# RL6955_IP_SVD register map
Vendor: Realtek
Registers are 32-bit, read-write, reset 0x0 unless marked. A register's access mark holds for its fields unless they carry their own. Offsets are from the block's base; [hi:lo] are bit positions.

## LDO_REG
Base 0x41000100
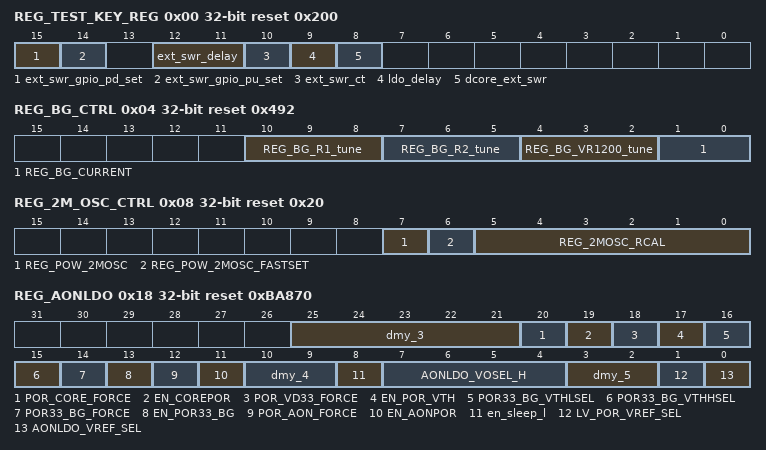
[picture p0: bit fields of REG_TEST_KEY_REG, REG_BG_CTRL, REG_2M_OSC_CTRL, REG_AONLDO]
0x00 REG_TEST_KEY_REG reset 0x200
  [15] ext_swr_gpio_pd_set — Set extenal swr gpio pull dn
  [14] ext_swr_gpio_pu_set — Set extenal swr gpio pull up
  [12:11] ext_swr_delay — External swr power stable time 2'b00: 750us 2'b01: 1ms 2'b10: 1.5ms 2'b11: 2ms
  [10] ext_swr_ct — 1: External swr can be controller by gpio 0: External swr has no controlled pin
  [9] ldo_delay — 1:Internal core ldo will be enable after chip reset , delay 3ms 0:NO extra delay applied
  [8] dcore_ext_swr — 1:use external swr for core power 0:use internal LDO for core power
0x04 REG_BG_CTRL reset 0x492
  [10:8] REG_BG_R1_tune, [7:5] REG_BG_R2_tune, [4:2] REG_BG_VR1200_tune, [1:0] REG_BG_CURRENT
0x08 REG_2M_OSC_CTRL access per field reset 0x20
  [7] REG_POW_2MOSC ro — // [RF][2MOSC] 1'b1 : enable
  [6] REG_POW_2MOSC_FASTSET rw — // [RF][2MOSC] REG_CTRL: enable fastset control
  [5:0] REG_2MOSC_RCAL rw — // [RF][2MOSC] adjust 2M osc frequency. Max freq:6'b111111
0x18 REG_AONLDO reset 0xBA870
  [25:21] dmy_3 — // [REGU][AONLDO] dummy
  [20] POR_CORE_FORCE
  [19] EN_COREPOR
  [18] POR_VD33_FORCE — POR_VTH_FORCE
  [17] EN_POR_VTH
  [16] POR33_BG_VTHLSEL — POR33_BG_VTHLSEL; 1:VREF=2.2V; 0:VREF=2.0V
  [15] POR33_BG_VTHHSEL — POR33_BG_VTHHSEL; 1:VREF=2.5V; 0:VREF=2.3V
  [14] POR33_BG_FORCE
  [13] EN_POR33_BG
  [12] POR_AON_FORCE
  [11] EN_AONPOR
  [10:9] dmy_4 — // [REGU][AONLDO] dummy
  [8] en_sleep_l — Enable LDO09H sleep mode 0 : disable (default) 1 : enable
  [7:4] AONLDO_VOSEL_H — AONLDO09 voltage select vref=0.540V / 0.475V --------------------------- 0000: 0.631V 0.556V 0001: 0.681V 0.600V 0010: 0.713V 0.628V 0011: 0.749V 0.659V 0100: 0.788V 0.694V 0101: 0.809V 0.712V 0110: 0.831V 0.732V 0111: 0.855V 0.753V 1000: 0.880V 0.775V 1001: 0.906V 0.798V 1010: 0.935V 0.823V 1011: 0.965V 0.850V 1100: 0.997V 0.878V 1101: 1.031V 0.908V 1110: 1.068V 0.940V 1111: 1.107V 0.975V
  [3:2] dmy_5 — // [REGU][AONLDO] dummy
  [1] LV_POR_VREF_SEL — LV_POR VREF 0 (default) VREF = 0P600V 1 VREF = 0P450V
  [0] AONLDO_VREF_SEL — AONLDO VREF_SEL 0 (default) VREF = 0P540V 1 VREF = 0P475V
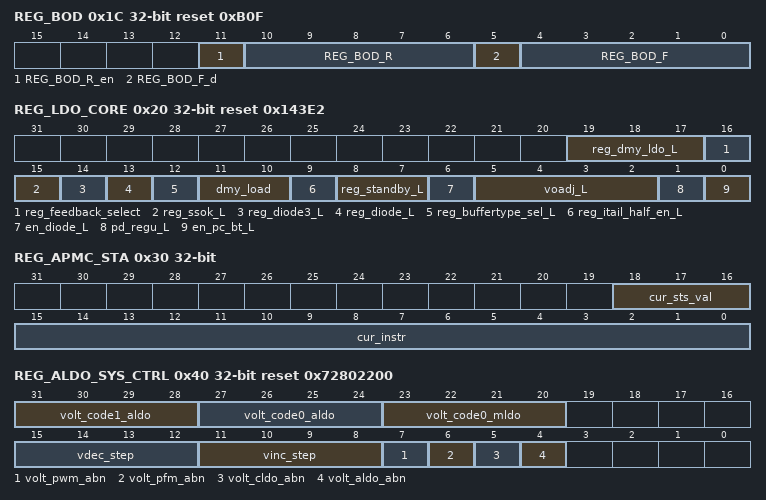
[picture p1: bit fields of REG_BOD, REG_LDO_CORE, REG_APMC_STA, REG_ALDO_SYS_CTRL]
0x1C REG_BOD reset 0xB0F
  [11] REG_BOD_R_en — // 0: disable BOD // 1: enable BOD
  [10:6] REG_BOD_R — 00000:3.325 00001:3.305 00010:3.255 00011:3.215 00100:3.175 00101:3.115 00110:3.055 00111:3.005 01000:2.956 01001:2.906 01010:2.866 01011:2.816 01100:2.776 01101:2.716 01110:2.666 01111:2.616 10000:2.556 10001:2.507(Default) 10010:2.457 10011:2.407 10100:2.357 10101:2.307 10110:2.267 10111:2.207 11000:2.148 11001:2.098 11010:2.048 11011:1.998 11100:1.948 11101:1.889 11110:1.829 11111:1.65
  [5] REG_BOD_F_d — // dummy
  [4:0] REG_BOD_F — 00000:3.325 00001:3.305 00010:3.255 00011:3.215 00100:3.175 00101:3.115 00110:3.055 00111:3.005 01000:2.956 01001:2.906 01010:2.866 01011:2.816 01100:2.776 01101:2.716 01110:2.666 01111:2.616 10000:2.556 10001:2.507 10010:2.457 10011:2.407 10100:2.357 10101:2.307 10110:2.267 10111:2.207 11000:2.148 11001:2.098 11010:2.048 11011:1.998(Default) 11100:1.948 11101:1.889 11110:1.829 11111:1.65
0x20 REG_LDO_CORE reset 0x143E2
  [19:17] reg_dmy_ldo_L — // [REGU][LDO] REG_CTRL //Dummy reg
  [16] reg_feedback_select — 0: feedback from AVDD_0P9H_LDO_OUTPUT_PAD 1: feedback from AVDD_0P9H_LDO_VOFB
  [15] reg_ssok_L — // [REGU][LDO] REG_CTRL // soft-start PWRMOS control // 0: medium PWRMOS (default) // 1: large PWRMOS
  [14] reg_diode3_L — // [REGU][LDO] REG_CTRL // PGATE diode3 clamp // 0: disable // 1: enable (default)
  [13] reg_diode_L — // [REGU][LDO] REG_CTRL // PGATE diode2 clamp // 0: disable (default) // 1: enable
  [12] reg_buffertype_sel_L — // [REGU][LDO] REG_CTRL // Buffer type select // 0: P-type buffer for 3.3V PWR (default) // 1: N-type buffer for 1.8V PWR
  [11:10] dmy_load — // [REGU][LDO] REG_CTRL // LDO dmy load controll // [1]dmy load // 1: enable // 0: disable (default) // [0] light dmy load // 1: enable // 0: disable (default)
  [9] reg_itail_half_en_L — // [REGU][LDO] REG_CTRL // Half tail current controll // 0: normal tail current (default) // 1: half tail current
  [8:7] reg_standby_L — // [REGU][LDO] REG_CTRL // [0] Iq controll // 0: Normal Iq (default) // 1: Standby Iq // [1] pwrmos controll // 0: Normal pwrmos (default) // 1: Standby pwrmos
  [6] en_diode_L — // [REGU][LDO] REG_CTRL // PGATE diode1 clamp //0:disable //1:enable (default)
  [5:2] voadj_L — // [REGU][LDO] REG_CTRL // LDO VOSEL // 0000, 0001, 0010, 0011: 648.2mV, 681.2mV, 714.0mV, 745.9mV // 0100, 0101, 0110, 0111: 776.2mV, 809.1mV, 839.6mV, 872.5mV // 1000 (default), 1001, 1010, 1011: 901.9mV, 933.4mV, 967.2mV, 996.1mV // 1100, 1101, 1110, 1111: 1026.7mV, 1059.2mV, 1085.0mV, 1112.1mV
  [1] pd_regu_L — // [REGU][LDO_UART] REG_CTRL // PowerDown CTRL // 0: normal-Mode(default) // 1: power-down Mode Note: This field is also controlled by syson pmc . When mldo_tmode is assert , pmc controller is not active
  [0] en_pc_bt_L — // [REGU][LDO] REG_CTRL // PWRCUT enable // 0: LDO-Mode (default) // 1: PWRCUT-Mode
0x28 REG_DUMMY_CTRL
  [15:0] REG_DMY_L — bit[8:7] -- 00: POR_AON; 01: RSTB_BOD_RESET; 10: RSTB_LV; 11:POR_OFF bit[6] -- 1: select CLK_OSC2M, CLK_OSC32K, CLK_OSC128K (watch REG_MUX_SEL_128K, REG_MUX_SEL_OSC) 0: select POR_AON, RSTB_BOD_RESET, RSTB_LV,POR_OFF
0x30 REG_APMC_STA ro
  [18:16] cur_sts_val — current regu status
  [15:0] cur_instr — regu pmc current instruction code
0x34 REG_APMC_VEC ro
  [15:0] cur_vec — regu pmc all intr vector
0x38 REG_APMC_ISR ro
  [15:0] cur_isr — regu pmc current processing isr, one hot
0x40 REG_ALDO_SYS_CTRL access per field reset 0x72802200
  [31:28] volt_code1_aldo rw — Aon LDO code1 , which indicate 0.8v
  [27:24] volt_code0_aldo rw — Aon LDO code0 , which indicate 0.7v
  [23:20] volt_code0_mldo rw — Mem LDO code0 , which indicate 1.8v
  [15:12] vdec_step rw — volt decrease step , unit in 100K cycle, acture value is this value + 1 Note: this is common for all LDO and SWR
  [11:8] vinc_step rw — volt decrease step , unit in 100K cycle, acture value is this value + 1 Note: this is common for all LDO and SWR
  [7] volt_pwm_abn ro — pwm volt adject abnormal statue . When happen , it is means current voltage is higher than request in a rising commond, same as falling case.
  [6] volt_pfm_abn ro — same as [7]
  [5] volt_cldo_abn ro — same as [7]
  [4] volt_aldo_abn ro — same as [7]
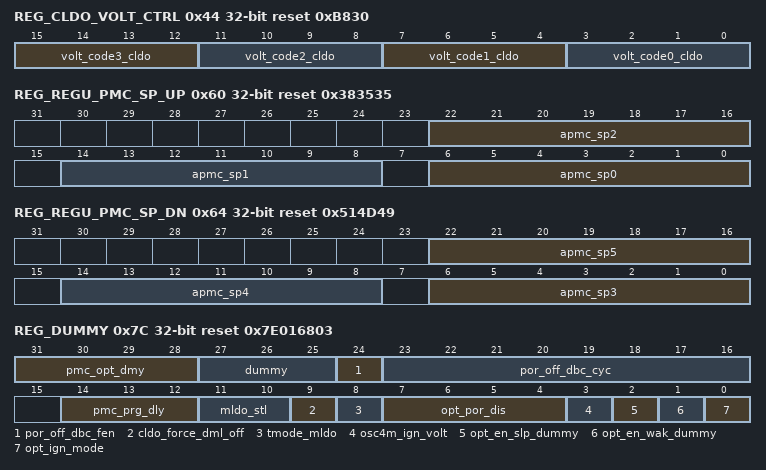
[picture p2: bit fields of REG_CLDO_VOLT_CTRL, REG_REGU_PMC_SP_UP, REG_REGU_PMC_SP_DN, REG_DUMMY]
0x44 REG_CLDO_VOLT_CTRL reset 0xB830
  [15:12] volt_code3_cldo — Core LDO code3 , which indicate 1.0v
  [11:8] volt_code2_cldo — Core LDO code2 , which indicate 0.9v
  [7:4] volt_code1_cldo — Core LDO code1 , which indicate 0.8v
  [3:0] volt_code0_cldo — Core LDO code0 , which indicate 0.7v , used in power cut mode(not used)
0x60 REG_REGU_PMC_SP_UP reset 0x383535
  [22:16] apmc_sp2 — Start Point for ST6 up
  [14:8] apmc_sp1 — Start Point for ST5 up
  [6:0] apmc_sp0 — Start Point for ST3/ST4 up (ST3 not support)
0x64 REG_REGU_PMC_SP_DN reset 0x514D49
  [22:16] apmc_sp5 — Start Point for ST2 dn , noused
  [14:8] apmc_sp4 — Start Point for ST4/ST3 dn
  [6:0] apmc_sp3 — Start Point for ST5 dn
0x70 REG_DEBUG ro
  [31:0] adbg_regu — REGU interface debug
0x7C REG_DUMMY reset 0x7E016803
  [31:28] pmc_opt_dmy
  [27:25] dummy
  [24] por_off_dbc_fen — Enable POR_OFF debounce
  [23:16] por_off_dbc_cyc — POR_OFF debounce cycle , base in 100K clock period
  [14:12] pmc_prg_dly — regu_pmc programmable delay value 0: 100us 1: 500us 2: 1ms 3: 2ms 4: 10ms 5: 50ms 6: 100ms 7: 200ms
  [11:10] mldo_stl — mem LDO power on stable wait time 00: 200us 01: 500us 10: 1ms 11: 2ms
  [9] cldo_force_dml_off — Force core ldo dummy load off , used when pc mode 1: force CLDO dummy load off , regu pmc will wirte this when enter pc mode 0: release
  [8] tmode_mldo — 3318 LDO enter testmode , and register setting will not controlled by pmc
  [7:4] opt_por_dis — option to disable POR for power saving when enter DSLP [0]: BOD , 1:disable when DSLP , 0:enable [1]: CORE_POR [2]: V33_POR_BG [3]: V33_POR_VTH
  [3] osc4m_ign_volt — Options if osc4m can auto require voltage , disable it may speedup reponse time when system never goto 0.7v 0. osc4m will send volt areq when osc4m enable or disable 1. osc4m never req volt change , make sure , system voltage will never goto 0.7v Note: RL6973 never goto 0.7v, fix 1
  [2] opt_en_slp_dummy — option for enable swr dummy load to speed up when pfm voltage falling. Default not enable , using a programmble delay to wait
  [1] opt_en_wak_dummy — option for enable swr dummy load to speed up when pfm -> pwm. if opt_wait_mode is 0 , this bit has no use
  [0] opt_ign_mode — option for ignore regu mode_l wait when pfm -> pwm. default not wait as usual
